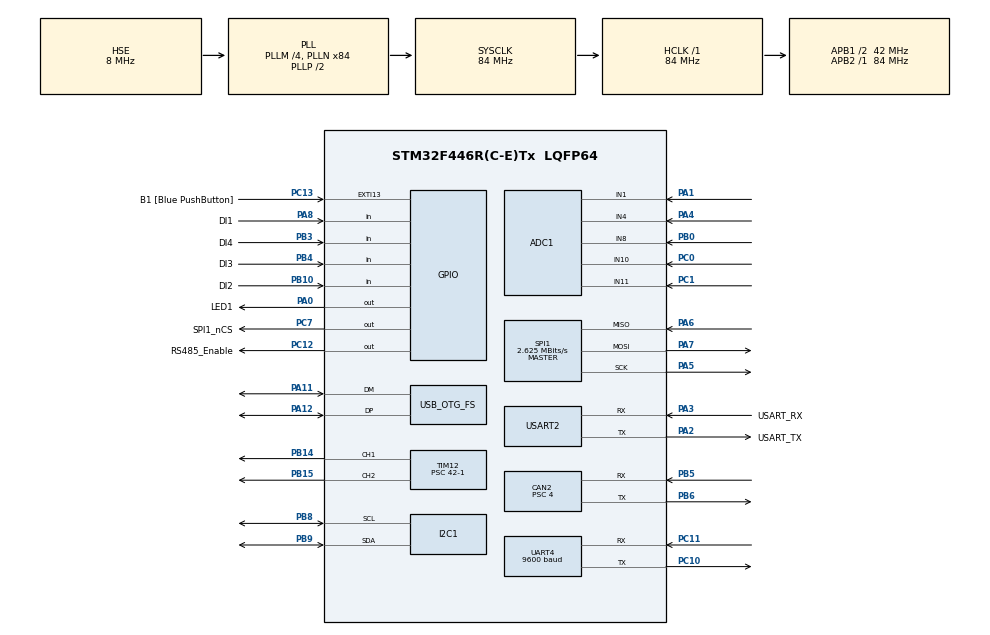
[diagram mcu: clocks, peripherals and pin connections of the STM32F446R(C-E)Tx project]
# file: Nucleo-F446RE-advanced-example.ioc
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ADC1.Channel-0\#ChannelRegularConversion=ADC_CHANNEL_10
ADC1.Channel-1\#ChannelRegularConversion=ADC_CHANNEL_11
ADC1.Channel-2\#ChannelRegularConversion=ADC_CHANNEL_8
ADC1.Channel-3\#ChannelRegularConversion=ADC_CHANNEL_4
ADC1.Channel-4\#ChannelRegularConversion=ADC_CHANNEL_1
ADC1.Channel-5\#ChannelRegularConversion=ADC_CHANNEL_VREFINT
ADC1.Channel-6\#ChannelRegularConversion=ADC_CHANNEL_TEMPSENSOR
ADC1.ClockPrescaler=ADC_CLOCK_SYNC_PCLK_DIV8
ADC1.EOCSelection=ADC_EOC_SEQ_CONV
ADC1.NbrOfConversion=7
ADC1.NbrOfConversionFlag=1
ADC1.Rank-0\#ChannelRegularConversion=1
ADC1.Rank-1\#ChannelRegularConversion=2
ADC1.Rank-2\#ChannelRegularConversion=3
ADC1.Rank-3\#ChannelRegularConversion=4
ADC1.Rank-4\#ChannelRegularConversion=5
ADC1.Rank-5\#ChannelRegularConversion=6
ADC1.Rank-6\#ChannelRegularConversion=7
ADC1.SamplingTime-0\#ChannelRegularConversion=ADC_SAMPLETIME_480CYCLES
ADC1.SamplingTime-1\#ChannelRegularConversion=ADC_SAMPLETIME_480CYCLES
ADC1.SamplingTime-2\#ChannelRegularConversion=ADC_SAMPLETIME_480CYCLES
ADC1.SamplingTime-3\#ChannelRegularConversion=ADC_SAMPLETIME_480CYCLES
ADC1.SamplingTime-4\#ChannelRegularConversion=ADC_SAMPLETIME_480CYCLES
ADC1.SamplingTime-5\#ChannelRegularConversion=ADC_SAMPLETIME_480CYCLES
ADC1.SamplingTime-6\#ChannelRegularConversion=ADC_SAMPLETIME_480CYCLES
ADC1.master=1
CAN2.BS1=CAN_BS1_15TQ
CAN2.BS2=CAN_BS2_5TQ
CAN2.CalculateBaudRate=500000
CAN2.CalculateTimeBit=2000
CAN2.CalculateTimeQuantum=95.23809523809524
CAN2.Prescaler=4
CAN2.SJW=CAN_SJW_1TQ
Dma.ADC1.0.Direction=DMA_PERIPH_TO_MEMORY
Dma.ADC1.0.FIFOMode=DMA_FIFOMODE_DISABLE
Dma.ADC1.0.Instance=DMA2_Stream0
Dma.ADC1.0.MemDataAlignment=DMA_MDATAALIGN_HALFWORD
Dma.ADC1.0.MemInc=DMA_MINC_ENABLE
Dma.ADC1.0.Mode=DMA_NORMAL
Dma.ADC1.0.PeriphDataAlignment=DMA_PDATAALIGN_HALFWORD
Dma.ADC1.0.PeriphInc=DMA_PINC_DISABLE
Dma.ADC1.0.Priority=DMA_PRIORITY_MEDIUM
Dma.Request0=ADC1
IWDG.Prescaler=IWDG_PRESCALER_256
IWDG.Reload=3875-1
Mcu.Family=STM32F4
Mcu.Name=STM32F446R(C-E)Tx
Mcu.Package=LQFP64
NVIC.CAN2_RX0_IRQn=true\:0\:0\:false\:false\:true\:true\:true\:true
NVIC.CAN2_RX1_IRQn=true\:0\:0\:false\:false\:true\:true\:true\:true
NVIC.DMA2_Stream0_IRQn=true\:0\:0\:false\:false\:true\:false\:true\:true
NVIC.EXTI15_10_IRQn=true\:0\:0\:false\:false\:true\:true\:true\:true
NVIC.OTG_FS_IRQn=true\:0\:0\:false\:false\:true\:true\:true\:true
NVIC.PriorityGroup=NVIC_PRIORITYGROUP_0
NVIC.UART4_IRQn=true\:0\:0\:false\:false\:true\:true\:true\:true
NVIC.USART2_IRQn=true\:0\:0\:false\:false\:true\:true\:true\:true
PA0-WKUP.GPIO_Label=LED1
PA0-WKUP.Signal=GPIO_Output
PA1.Signal=ADCx_IN1
PA11.Mode=Device_Only
PA11.Signal=USB_OTG_FS_DM
PA12.Mode=Device_Only
PA12.Signal=USB_OTG_FS_DP
PA13.GPIO_Label=TMS
PA13.Mode=Serial_Wire
PA13.Signal=SYS_JTMS-SWDIO
PA14.GPIO_Label=TCK
PA14.Mode=Serial_Wire
PA14.Signal=SYS_JTCK-SWCLK
PA2.GPIO_Label=USART_TX
PA2.GPIO_PuPd=GPIO_PULLUP
PA2.Mode=Asynchronous
PA2.Signal=USART2_TX
PA3.GPIO_Label=USART_RX
PA3.GPIO_PuPd=GPIO_PULLUP
PA3.Mode=Asynchronous
PA3.Signal=USART2_RX
PA4.Signal=ADCx_IN4
PA5.Mode=Full_Duplex_Master
PA5.Signal=SPI1_SCK
PA6.Mode=Full_Duplex_Master
PA6.Signal=SPI1_MISO
PA7.Mode=Full_Duplex_Master
PA7.Signal=SPI1_MOSI
PA8.GPIO_Label=DI1
PA8.GPIO_PuPd=GPIO_PULLUP
PA8.Signal=GPIO_Input
PB0.Signal=ADCx_IN8
PB10.GPIO_Label=DI2
PB10.GPIO_PuPd=GPIO_PULLUP
PB10.Signal=GPIO_Input
PB14.Signal=S_TIM12_CH1
PB15.Signal=S_TIM12_CH2
PB3.GPIO_Label=DI4
PB3.GPIO_PuPd=GPIO_PULLUP
PB3.Signal=GPIO_Input
PB4.GPIO_Label=DI3
PB4.GPIO_PuPd=GPIO_PULLUP
PB4.Signal=GPIO_Input
PB5.Mode=CAN_Activate
PB5.Signal=CAN2_RX
PB6.Mode=CAN_Activate
PB6.Signal=CAN2_TX
PB8.Mode=I2C
PB8.Signal=I2C1_SCL
PB9.Mode=I2C
PB9.Signal=I2C1_SDA
PC0.Signal=ADCx_IN10
PC1.Signal=ADCx_IN11
PC10.GPIO_PuPd=GPIO_PULLUP
PC10.Mode=Asynchronous
PC10.Signal=UART4_TX
PC11.GPIO_PuPd=GPIO_PULLUP
PC11.Mode=Asynchronous
PC11.Signal=UART4_RX
PC12.GPIO_Label=RS485_Enable
PC12.Signal=GPIO_Output
PC13.GPIO_Label=B1 [Blue PushButton]
PC13.GPIO_ModeDefaultEXTI=GPIO_MODE_IT_FALLING
PC13.Signal=GPXTI13
PC14-OSC32_IN.Mode=LSE-External-Oscillator
PC14-OSC32_IN.Signal=RCC_OSC32_IN
PC15-OSC32_OUT.Mode=LSE-External-Oscillator
PC15-OSC32_OUT.Signal=RCC_OSC32_OUT
PC7.GPIO_Label=SPI1_nCS
PC7.PinState=GPIO_PIN_SET
PC7.Signal=GPIO_Output
PH0-OSC_IN.Mode=HSE-External-Oscillator
PH0-OSC_IN.Signal=RCC_OSC_IN
PH1-OSC_OUT.Mode=HSE-External-Oscillator
PH1-OSC_OUT.Signal=RCC_OSC_OUT
ProjectManager.HeapSize=0x200
ProjectManager.StackSize=0x400
ProjectManager.TargetToolchain=STM32CubeIDE
RCC.48MHZClocksFreq_Value=84000000
RCC.AHBFreq_Value=84000000
RCC.APB1CLKDivider=RCC_HCLK_DIV2
RCC.APB1Freq_Value=42000000
RCC.APB1TimFreq_Value=84000000
RCC.APB2Freq_Value=84000000
RCC.APB2TimFreq_Value=84000000
RCC.CortexFreq_Value=84000000
RCC.FLatency-AdvancedSettings=FLASH_LATENCY_2
RCC.HCLKFreq_Value=84000000
RCC.HSE_VALUE=8000000
RCC.HSI_VALUE=16000000
RCC.PLLM=4
RCC.PLLN=84
RCC.PLLQ=3
RCC.PLLSAIM=4
RCC.PLLSAIN=96
RCC.PLLSAIP=RCC_PLLSAIP_DIV4
RCC.RCC_RTC_Clock_SourceVirtual=RCC_RTCCLKSOURCE_LSE
RCC.SYSCLKFreq_VALUE=84000000
RCC.SYSCLKSource=RCC_SYSCLKSOURCE_PLLCLK
RCC.USBCLockSelection=RCC_CLK48CLKSOURCE_PLLSAIP
RCC.USBFreq_Value=48000000
RCC.VCOOutputFreq_Value=168000000
SH.ADCx_IN1.0=ADC1_IN1,IN1
SH.ADCx_IN10.0=ADC1_IN10,IN10
SH.ADCx_IN11.0=ADC1_IN11,IN11
SH.ADCx_IN4.0=ADC1_IN4,IN4
SH.ADCx_IN8.0=ADC1_IN8,IN8
SH.S_TIM12_CH1.0=TIM12_CH1,PWM Generation1 CH1
SH.S_TIM12_CH2.0=TIM12_CH2,PWM Generation2 CH2
SPI1.BaudRatePrescaler=SPI_BAUDRATEPRESCALER_32
SPI1.CLKPhase=SPI_PHASE_2EDGE
SPI1.CalculateBaudRate=2.625 MBits/s
SPI1.Direction=SPI_DIRECTION_2LINES
SPI1.FirstBit=SPI_FIRSTBIT_MSB
SPI1.Mode=SPI_MODE_MASTER
SPI1.VirtualType=VM_MASTER
TIM12.Channel-PWM\ Generation1\ CH1=TIM_CHANNEL_1
TIM12.Channel-PWM\ Generation2\ CH2=TIM_CHANNEL_2
TIM12.Period=1024-1
TIM12.Prescaler=42-1
TIM12.Pulse-PWM\ Generation1\ CH1=8-1
TIM12.Pulse-PWM\ Generation2\ CH2=8-1
UART4.BaudRate=9600
UART4.VirtualMode=Asynchronous
USART2.VirtualMode=VM_ASYNC
USB_DEVICE.CLASS_NAME_FS=CDC
USB_DEVICE.VirtualMode-CDC_FS=Cdc
USB_DEVICE.VirtualModeFS=Cdc_FS
USB_OTG_FS.VirtualMode=Device_Only
VP_ADC1_TempSens_Input.Mode=IN-TempSens
VP_ADC1_Vref_Input.Mode=IN-Vrefint
VP_IWDG_VS_IWDG.Mode=IWDG_Activate
VP_RTC_VS_RTC_Activate.Mode=RTC_Enabled
VP_TIM12_VS_ClockSourceINT.Mode=Internal
VP_USB_DEVICE_VS_USB_DEVICE_CDC_FS.Mode=CDC_FS
board=NUCLEO-F446RE

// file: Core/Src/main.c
/* USER CODE BEGIN Header */
/**
 ******************************************************************************
 * @file           : main.c
 * @brief          : Main program body
 ******************************************************************************
 * @attention
 *
 * Copyright (c) 2026 STMicroelectronics.
 * All rights reserved.
 *
 * This software is licensed under terms that can be found in the LICENSE file
 * in the root directory of this software component.
 * If no LICENSE file comes with this software, it is provided AS-IS.
 *
 ******************************************************************************
 */
/* USER CODE END Header */
#include "main.h"
#include "adc.h"
#include "can.h"
#include "dma.h"
#include "i2c.h"
#include "iwdg.h"
#include "rtc.h"
#include "spi.h"
#include "tim.h"
#include "usart.h"
#include "usb_device.h"
#include "gpio.h"

/* USER CODE BEGIN Includes */

#include "app_demo.h"
#include <stdio.h>
/* USER CODE END Includes */

void SystemClock_Config(void);

int main(void)
{

  /* MCU Configuration--------------------------------------------------------*/

  /* Reset of all peripherals, Initializes the Flash interface and the Systick. */
  HAL_Init();

  /* Configure the system clock */
  SystemClock_Config();

  /* Initialize all configured peripherals */
  MX_GPIO_Init();
  MX_DMA_Init();
  MX_USART2_UART_Init();
  MX_ADC1_Init();
  MX_SPI1_Init();
  MX_I2C1_Init();
  MX_UART4_Init();
  MX_TIM12_Init();
  MX_IWDG_Init();
  MX_CAN2_Init();
  MX_RTC_Init();
  MX_USB_DEVICE_Init();
  /* USER CODE BEGIN 2 */

  app_demo_main();

  /* USER CODE END 2 */

  /* Infinite loop */
	while (1) {

    /* USER CODE BEGIN 3 */
		printf("you should never read this!\n");
	}
  /* USER CODE END 3 */
}

void SystemClock_Config(void)
{
  RCC_OscInitTypeDef RCC_OscInitStruct = {0};
  RCC_ClkInitTypeDef RCC_ClkInitStruct = {0};

  /** Configure the main internal regulator output voltage
  */
  __HAL_RCC_PWR_CLK_ENABLE();
  __HAL_PWR_VOLTAGESCALING_CONFIG(PWR_REGULATOR_VOLTAGE_SCALE3);

  /** Initializes the RCC Oscillators according to the specified parameters
  * in the RCC_OscInitTypeDef structure.
  */
  RCC_OscInitStruct.OscillatorType = RCC_OSCILLATORTYPE_LSI|RCC_OSCILLATORTYPE_HSE
                              |RCC_OSCILLATORTYPE_LSE;
  RCC_OscInitStruct.HSEState = RCC_HSE_ON;
  RCC_OscInitStruct.LSEState = RCC_LSE_ON;
  RCC_OscInitStruct.LSIState = RCC_LSI_ON;
  RCC_OscInitStruct.PLL.PLLState = RCC_PLL_ON;
  RCC_OscInitStruct.PLL.PLLSource = RCC_PLLSOURCE_HSE;
  RCC_OscInitStruct.PLL.PLLM = 4;
  RCC_OscInitStruct.PLL.PLLN = 84;
  RCC_OscInitStruct.PLL.PLLP = RCC_PLLP_DIV2;
  RCC_OscInitStruct.PLL.PLLQ = 3;
  RCC_OscInitStruct.PLL.PLLR = 2;
  if (HAL_RCC_OscConfig(&RCC_OscInitStruct) != HAL_OK)
  {
    Error_Handler();
  }

  /** Initializes the CPU, AHB and APB buses clocks
  */
  RCC_ClkInitStruct.ClockType = RCC_CLOCKTYPE_HCLK|RCC_CLOCKTYPE_SYSCLK
                              |RCC_CLOCKTYPE_PCLK1|RCC_CLOCKTYPE_PCLK2;
  RCC_ClkInitStruct.SYSCLKSource = RCC_SYSCLKSOURCE_PLLCLK;
  RCC_ClkInitStruct.AHBCLKDivider = RCC_SYSCLK_DIV1;
  RCC_ClkInitStruct.APB1CLKDivider = RCC_HCLK_DIV2;
  RCC_ClkInitStruct.APB2CLKDivider = RCC_HCLK_DIV1;

  if (HAL_RCC_ClockConfig(&RCC_ClkInitStruct, FLASH_LATENCY_2) != HAL_OK)
  {
    Error_Handler();
  }
}

void Error_Handler(void)
{
	__disable_irq();
	while (1) {
	}
}
